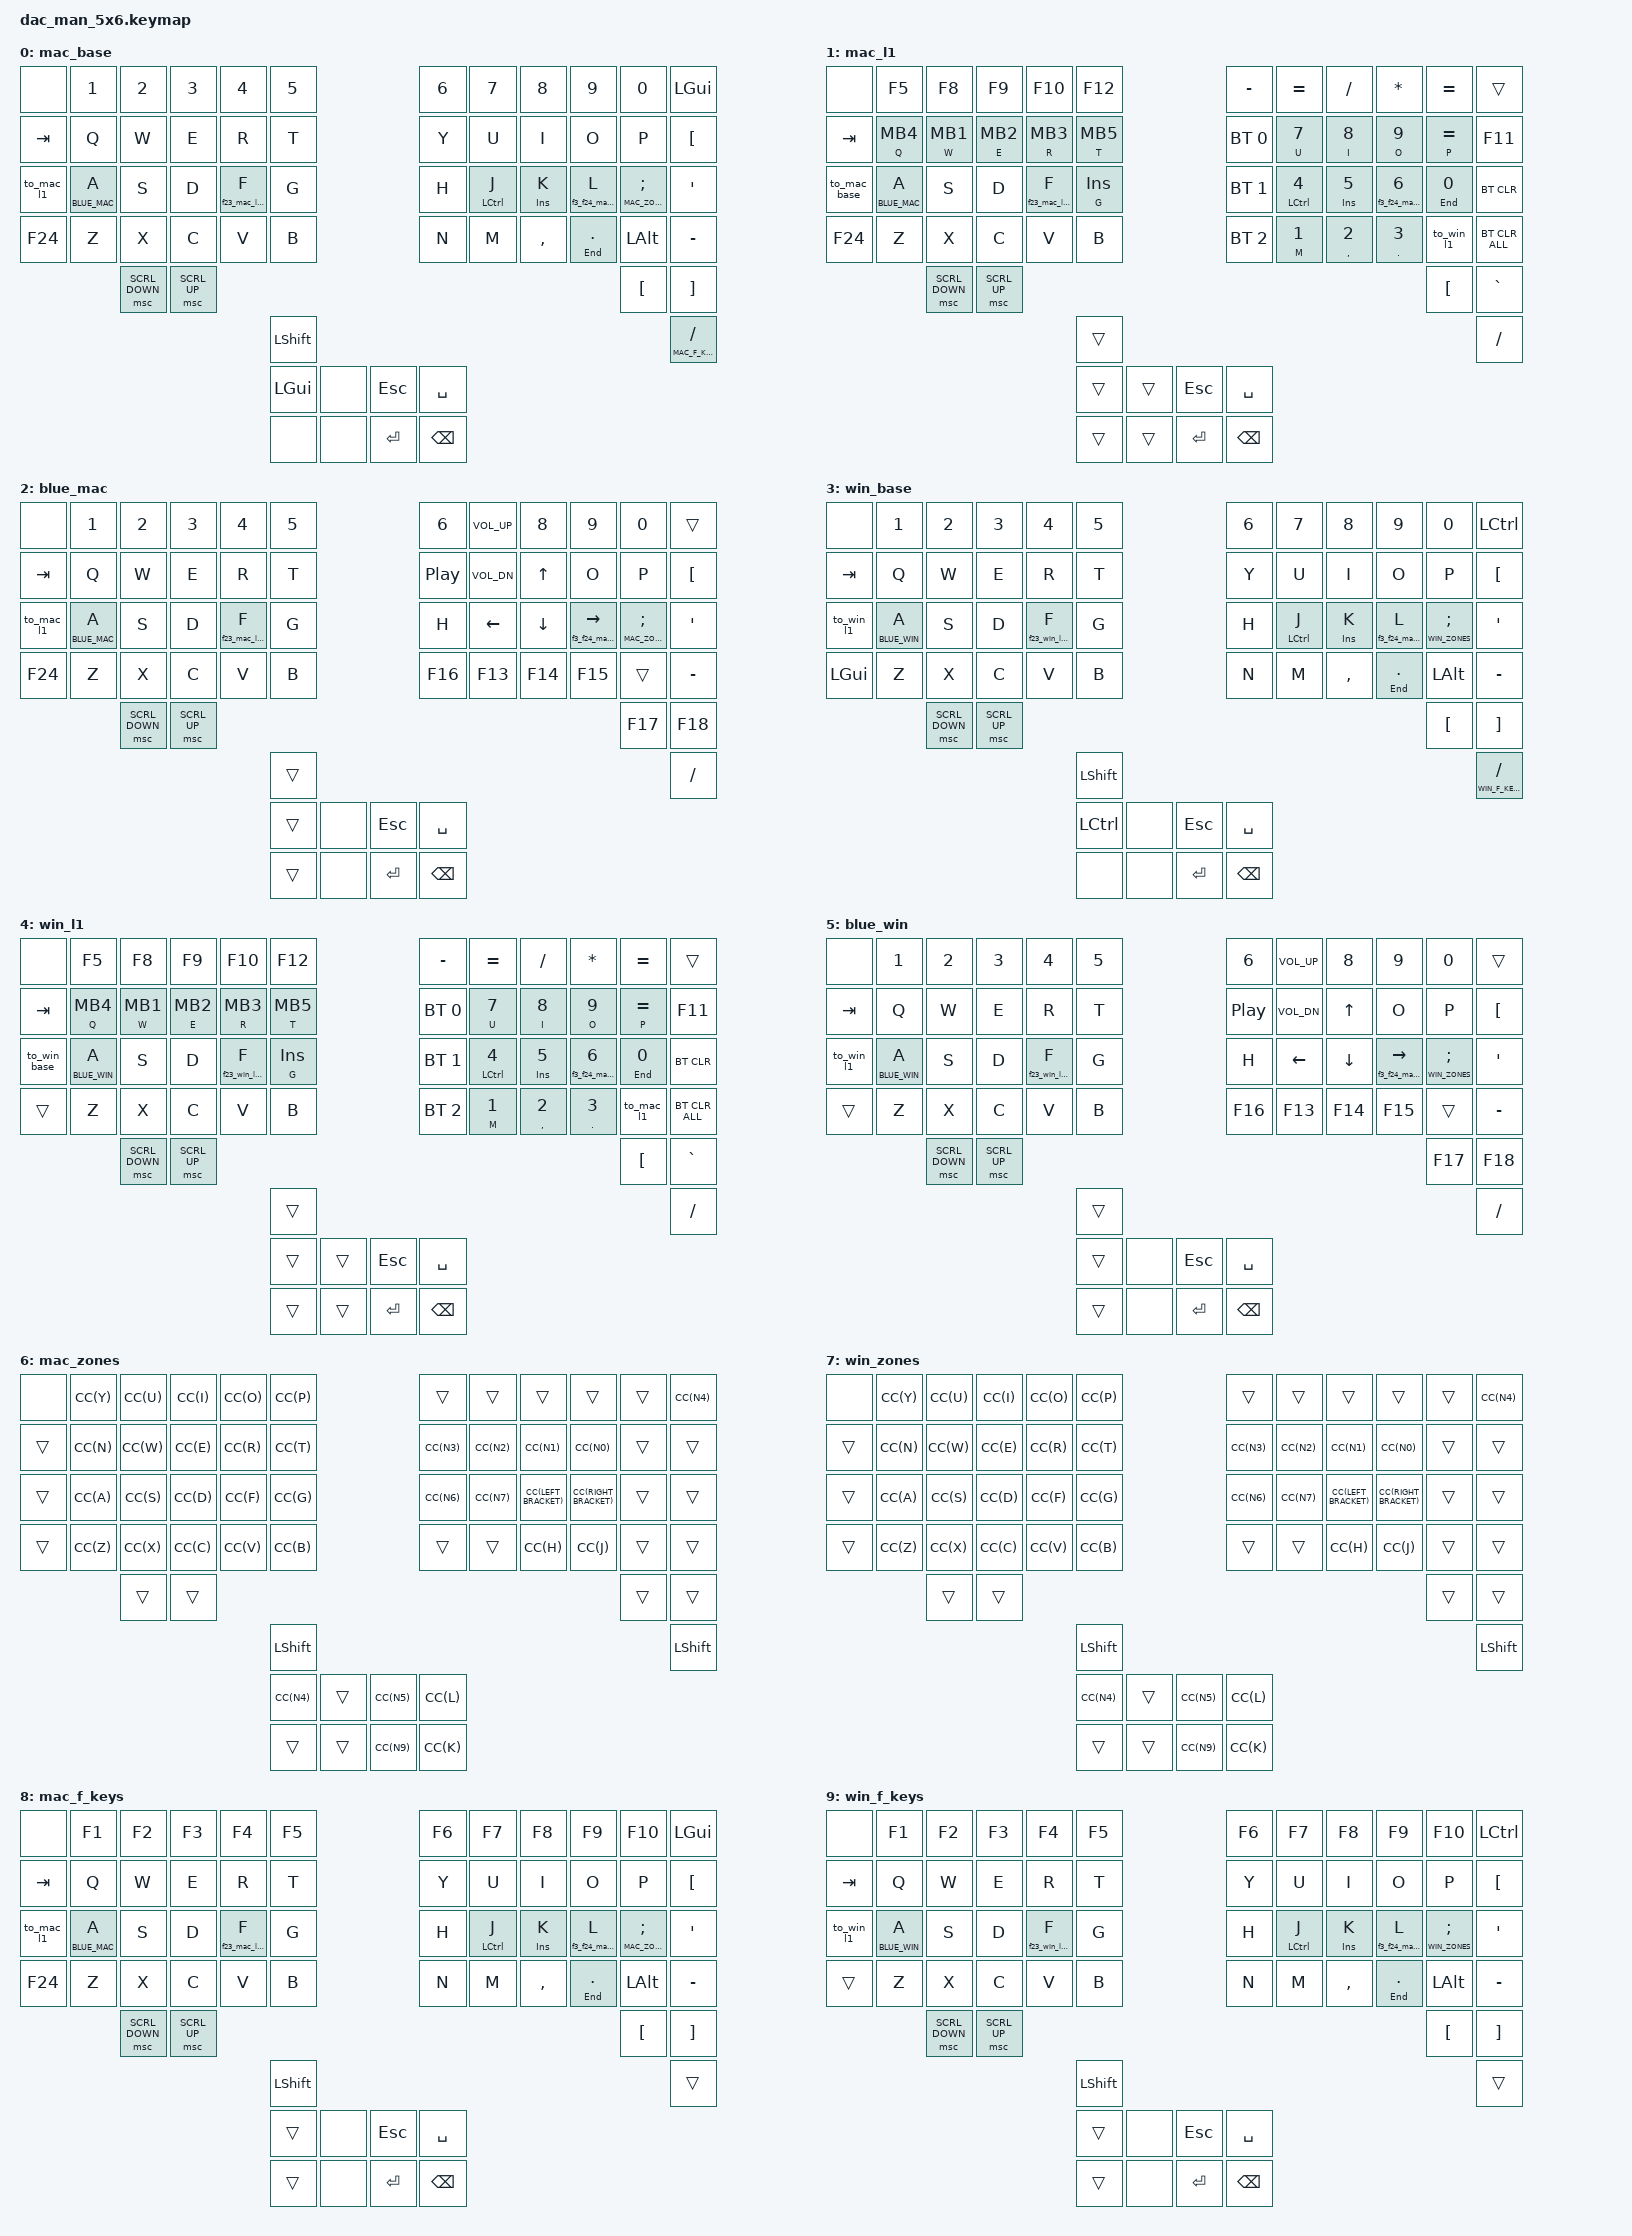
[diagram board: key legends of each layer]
#include <behaviors.dtsi>
#include <dt-bindings/zmk/bt.h>
#include <dt-bindings/zmk/keys.h>
#include <dt-bindings/zmk/pointing.h>

#define MAC_BASE   0
#define MAC_L1     1
#define BLUE_MAC   2
#define WIN_BASE   3
#define WIN_L1     4
#define BLUE_WIN   5
#define MAC_ZONES  6
#define WIN_ZONES  7
#define MAC_F_KEYS 8
#define WIN_F_KEYS 9

// Hyper key (Shift + Ctrl + Alt + Gui)
#define HYP(key) LS(LC(LA(LG(key))))
// Command + Control
#define CC(key) LC(LG(key))

/ {
    macros {
        to_mac_base: to_mac_base {
            compatible = "zmk,behavior-macro";
            #binding-cells = <0>;
            bindings = <&to MAC_BASE>, <&kp F19>;
        };

        to_mac_l1: to_mac_l1 {
            compatible = "zmk,behavior-macro";
            #binding-cells = <0>;
            bindings = <&to MAC_L1>, <&kp F20>;
        };

        to_win_base: to_win_base {
            compatible = "zmk,behavior-macro";
            #binding-cells = <0>;
            bindings = <&to WIN_BASE>, <&kp F21>;
        };

        to_win_l1: to_win_l1 {
            compatible = "zmk,behavior-macro";
            #binding-cells = <0>;
            bindings = <&to WIN_L1>, <&kp F22>;
        };

        f23_mac_layer: f23_mac_layer {
            compatible = "zmk,behavior-macro-one-param";
            #binding-cells = <1>;
            wait-ms = <0>;
            tap-ms = <0>;
            bindings =
                <&macro_press>, <&mo BLUE_MAC>,
                <&macro_tap>, <&kp F23>,
                <&macro_pause_for_release>,
                <&macro_release>, <&mo BLUE_MAC>;
        };

        f23_win_layer: f23_win_layer {
            compatible = "zmk,behavior-macro-one-param";
            #binding-cells = <1>;
            wait-ms = <0>;
            tap-ms = <0>;
            bindings =
                <&macro_press>, <&mo BLUE_WIN>,
                <&macro_tap>, <&kp F23>,
                <&macro_pause_for_release>,
                <&macro_release>, <&mo BLUE_WIN>;
        };

        f3_f24_macro: f3_f24_macro {
            compatible = "zmk,behavior-macro-one-param";
            #binding-cells = <1>;
            wait-ms = <0>;
            tap-ms = <0>;
            bindings =
                <&macro_press>, <&kp F24>,
                <&macro_press>, <&kp F3>,
                <&macro_pause_for_release>,
                <&macro_release>, <&kp F3>,
                <&macro_release>, <&kp F24>;
        };
    };

    behaviors {
        ht_tog: hold_tap_toggle {
            compatible = "zmk,behavior-hold-tap";
            #binding-cells = <2>;
            flavor = "tap-preferred";
            tapping-term-ms = <300>;
            require-prior-idle-ms = <350>;
            bindings = <&tog>, <&kp>;
        };

        ht_kp: hold_tap_key {
            compatible = "zmk,behavior-hold-tap";
            #binding-cells = <2>;
            flavor = "tap-preferred";
            tapping-term-ms = <300>;
            require-prior-idle-ms = <350>;
            bindings = <&kp>, <&kp>;
        };

        lt_kp: layer_tap_key {
            compatible = "zmk,behavior-hold-tap";
            #binding-cells = <2>;
            flavor = "tap-preferred";
            tapping-term-ms = <300>;
            require-prior-idle-ms = <350>;
            bindings = <&mo>, <&kp>;
        };

        lt_long: layer_tap_long {
            compatible = "zmk,behavior-hold-tap";
            #binding-cells = <2>;
            flavor = "tap-preferred";
            tapping-term-ms = <500>;
            require-prior-idle-ms = <350>;
            bindings = <&mo>, <&kp>;
        };

        ht_f_mac: ht_f_mac {
            compatible = "zmk,behavior-hold-tap";
            #binding-cells = <2>;
            flavor = "tap-preferred";
            tapping-term-ms = <300>;
            require-prior-idle-ms = <350>;
            bindings = <&f23_mac_layer>, <&kp>;
        };

        ht_f_win: ht_f_win {
            compatible = "zmk,behavior-hold-tap";
            #binding-cells = <2>;
            flavor = "tap-preferred";
            tapping-term-ms = <300>;
            require-prior-idle-ms = <350>;
            bindings = <&f23_win_layer>, <&kp>;
        };

        ht_l1_kp: hold_tap_l1_kp {
            compatible = "zmk,behavior-hold-tap";
            #binding-cells = <2>;
            flavor = "tap-preferred";
            tapping-term-ms = <500>;
            require-prior-idle-ms = <150>;
            bindings = <&kp>, <&kp>;
        };

        ht_l1_mkp: hold_tap_l1_mkp {
            compatible = "zmk,behavior-hold-tap";
            #binding-cells = <2>;
            flavor = "tap-preferred";
            tapping-term-ms = <500>;
            require-prior-idle-ms = <150>;
            bindings = <&kp>, <&mkp>;
        };

        ht_f3_f24: ht_f3_f24 {
            compatible = "zmk,behavior-hold-tap";
            #binding-cells = <2>;
            flavor = "tap-preferred";
            tapping-term-ms = <300>;
            require-prior-idle-ms = <350>;
            bindings = <&f3_f24_macro>, <&kp>;
        };

        ht_l1_f3_f24: ht_l1_f3_f24 {
            compatible = "zmk,behavior-hold-tap";
            #binding-cells = <2>;
            flavor = "tap-preferred";
            tapping-term-ms = <500>;
            require-prior-idle-ms = <150>;
            bindings = <&f3_f24_macro>, <&kp>;
        };
    };

    keymap {
        compatible = "zmk,keymap";

        // ================= MAC OS LAYERS =================

        mac_base {
            bindings = <
&none       &kp N1              &kp N2          &kp N3          &kp N4        &kp N5                                                                                                                                                                                                                                                                                                                        &kp N6          &kp N7         &kp N8          &kp N9             &kp N0                     &kp LGUI
&kp TAB     &kp Q               &kp W           &kp E           &kp R         &kp T                                                                                                                                                                                                                                                                                                                         &kp Y           &kp U          &kp I           &kp O              &kp P                      &kp LEFT_BRACKET
&to_mac_l1  &ht_tog BLUE_MAC A  &kp S           &kp D           &ht_f_mac 0 F &kp G                                                                                                                                                                                                                                                                                                                         &kp H           &ht_kp LCTRL J &ht_kp INSERT K &ht_f3_f24 0 L     &lt_kp MAC_ZONES SEMICOLON &kp SQT
&kp F24     &kp Z               &kp X           &kp C           &kp V         &kp B                                                                                                                                                                                                                                                                                                                         &kp N           &kp M          &kp COMMA       &ht_kp END DOT     &kp LALT                   &kp MINUS
                                &msc SCRL_DOWN  &msc SCRL_UP                                                                                                                                                                                                                                                                                                                                                                                                                      &kp LEFT_BRACKET           &kp RIGHT_BRACKET
                                                                              &kp LSHIFT                                                                                                                                                                                                                                                                                                                                                                                                                 &lt_long MAC_F_KEYS SLASH
                                                                                              &kp LGUI  &none  &kp ESCAPE  &kp SPACE
                                                                                              &none     &none  &kp RET     &kp BACKSPACE
            >;
        };

        mac_l1 {
            bindings = <
&none        &kp F5             &kp F8           &kp F9           &kp F10          &kp F12                                                                                                                                                                                                                                                                                                                      &kp MINUS       &kp EQUAL            &kp SLASH            &kp ASTERISK          &kp EQUAL              &trans
&kp TAB      &ht_l1_mkp Q MB4   &ht_l1_mkp W MB1 &ht_l1_mkp E MB2 &ht_l1_mkp R MB3 &ht_l1_mkp T MB5                                                                                                                                                                                                                                                                                                             &bt BT_SEL 0    &ht_l1_kp U NUMBER_7 &ht_l1_kp I NUMBER_8 &ht_l1_kp O NUMBER_9  &ht_l1_kp P EQUAL      &kp F11
&to_mac_base &ht_tog BLUE_MAC A &kp S            &kp D            &ht_f_mac 0 F    &ht_l1_kp G INSERT                                                                                                                                                                                                                                                                                                           &bt BT_SEL 1    &ht_l1_kp LCTRL NUMBER_4 &ht_l1_kp INSERT NUMBER_5 &ht_l1_f3_f24 0 NUMBER_6 &ht_l1_kp END NUMBER_0 &bt BT_CLR
&kp F24      &kp Z              &kp X            &kp C            &kp V            &kp B                                                                                                                                                                                                                                                                                                                        &bt BT_SEL 2    &ht_l1_kp M NUMBER_1 &ht_l1_kp COMMA NUMBER_2 &ht_l1_kp DOT NUMBER_3 &to_win_l1             &bt BT_CLR_ALL
                                &msc SCRL_DOWN   &msc SCRL_UP                                                                                                                                                                                                                                                                                                                                                                                                                                       &kp LEFT_BRACKET       &kp GRAVE
                                                                                   &trans                                                                                                                                                                                                                                                                                                                                                                                                                                &kp SLASH
                                                                                                      &trans    &trans &kp ESC    &kp SPACE
                                                                                                      &trans    &trans &kp ENTER  &kp BACKSPACE
            >;
        };

        blue_mac {
            bindings = <
&none       &kp N1              &kp N2          &kp N3          &kp N4        &kp N5                                                                                                                                                                                                                                                                                                                        &kp N6          &kp C_VOL_UP  &kp N8          &kp N9             &kp N0                     &trans
&kp TAB     &kp Q               &kp W           &kp E           &kp R         &kp T                                                                                                                                                                                                                                                                                                                         &kp C_PP        &kp C_VOL_DN  &kp UP_ARROW    &kp O              &kp P                      &kp LEFT_BRACKET
&to_mac_l1  &ht_tog BLUE_MAC A  &kp S           &kp D           &ht_f_mac 0 F &kp G                                                                                                                                                                                                                                                                                                                         &kp H           &kp LEFT      &kp DOWN        &ht_f3_f24 0 RIGHT &lt_kp MAC_ZONES SEMICOLON &kp SQT
&kp F24     &kp Z               &kp X           &kp C           &kp V         &kp B                                                                                                                                                                                                                                                                                                                         &kp F16         &kp F13       &kp F14         &kp F15            &trans                     &kp MINUS
                                &msc SCRL_DOWN  &msc SCRL_UP                                                                                                                                                                                                                                                                                                                                                                                                                      &kp F17                    &kp F18
                                                                              &trans                                                                                                                                                                                                                                                                                                                                                                                                                     &kp SLASH
                                                                                              &trans    &none  &kp ESCAPE  &kp SPACE
                                                                                              &trans    &none  &kp RET     &kp BACKSPACE
            >;
        };

        // ================= WINDOWS LAYERS =================

        win_base {
            bindings = <
&none         &kp N1              &kp N2          &kp N3          &kp N4        &kp N5                                                                                                                                                                                                                                                                                                                        &kp N6          &kp N7         &kp N8          &kp N9             &kp N0                     &kp LCTRL
&kp TAB       &kp Q               &kp W           &kp E           &kp R         &kp T                                                                                                                                                                                                                                                                                                                         &kp Y           &kp U          &kp I           &kp O              &kp P                      &kp LEFT_BRACKET
&to_win_l1    &ht_tog BLUE_WIN A  &kp S           &kp D           &ht_f_win 0 F &kp G                                                                                                                                                                                                                                                                                                                         &kp H           &ht_kp LCTRL J &ht_kp INSERT K &ht_f3_f24 0 L     &lt_kp WIN_ZONES SEMICOLON &kp SQT
&kp LGUI      &kp Z               &kp X           &kp C           &kp V         &kp B                                                                                                                                                                                                                                                                                                                         &kp N           &kp M          &kp COMMA       &ht_kp END DOT     &kp LALT                   &kp MINUS
                                  &msc SCRL_DOWN  &msc SCRL_UP                                                                                                                                                                                                                                                                                                                                                                                                                        &kp LEFT_BRACKET           &kp RIGHT_BRACKET
                                                                                &kp LSHIFT                                                                                                                                                                                                                                                                                                                                                                                                                   &lt_long WIN_F_KEYS SLASH
                                                                                                &kp LCTRL         &none  &kp ESCAPE  &kp SPACE
                                                                                                &none             &none  &kp RET     &kp BACKSPACE
            >;
        };

        win_l1 {
            bindings = <
&none         &kp F5              &kp F8           &kp F9           &kp F10          &kp F12                                                                                                                                                                                                                                                                                                                      &kp MINUS       &kp EQUAL            &kp SLASH            &kp ASTERISK          &kp EQUAL              &trans
&kp TAB       &ht_l1_mkp Q MB4    &ht_l1_mkp W MB1 &ht_l1_mkp E MB2 &ht_l1_mkp R MB3 &ht_l1_mkp T MB5                                                                                                                                                                                                                                                                                                             &bt BT_SEL 0    &ht_l1_kp U NUMBER_7 &ht_l1_kp I NUMBER_8 &ht_l1_kp O NUMBER_9  &ht_l1_kp P EQUAL      &kp F11
&to_win_base  &ht_tog BLUE_WIN A  &kp S            &kp D            &ht_f_win 0 F    &ht_l1_kp G INSERT                                                                                                                                                                                                                                                                                                           &bt BT_SEL 1    &ht_l1_kp LCTRL NUMBER_4 &ht_l1_kp INSERT NUMBER_5 &ht_l1_f3_f24 0 NUMBER_6 &ht_l1_kp END NUMBER_0 &bt BT_CLR
&trans        &kp Z               &kp X            &kp C            &kp V            &kp B                                                                                                                                                                                                                                                                                                                        &bt BT_SEL 2    &ht_l1_kp M NUMBER_1 &ht_l1_kp COMMA NUMBER_2 &ht_l1_kp DOT NUMBER_3 &to_mac_l1             &bt BT_CLR_ALL
                                  &msc SCRL_DOWN   &msc SCRL_UP                                                                                                                                                                                                                                                                                                                                                                                                                                       &kp LEFT_BRACKET       &kp GRAVE
                                                                                     &trans                                                                                                                                                                                                                                                                                                                                                                                                                                  &kp SLASH
                                                                                                        &trans            &trans &kp ESC    &kp SPACE
                                                                                                        &trans            &trans &kp ENTER  &kp BACKSPACE
            >;
        };

        blue_win {
            bindings = <
&none         &kp N1              &kp N2          &kp N3          &kp N4        &kp N5                                                                                                                                                                                                                                                                                                                        &kp N6          &kp C_VOL_UP  &kp N8          &kp N9             &kp N0                     &trans
&kp TAB       &kp Q               &kp W           &kp E           &kp R         &kp T                                                                                                                                                                                                                                                                                                                         &kp C_PP        &kp C_VOL_DN  &kp UP_ARROW    &kp O              &kp P                      &kp LEFT_BRACKET
&to_win_l1    &ht_tog BLUE_WIN A  &kp S           &kp D           &ht_f_win 0 F &kp G                                                                                                                                                                                                                                                                                                                         &kp H           &kp LEFT      &kp DOWN        &ht_f3_f24 0 RIGHT &lt_kp WIN_ZONES SEMICOLON &kp SQT
&trans        &kp Z               &kp X           &kp C           &kp V         &kp B                                                                                                                                                                                                                                                                                                                         &kp F16         &kp F13       &kp F14         &kp F15            &trans                     &kp MINUS
                                  &msc SCRL_DOWN  &msc SCRL_UP                                                                                                                                                                                                                                                                                                                                                                                                                        &kp F17                    &kp F18
                                                                                &trans                                                                                                                                                                                                                                                                                                                                                                                                                       &kp SLASH
                                                                                                &trans    &none  &kp ESCAPE  &kp SPACE
                                                                                                &trans    &none  &kp RET     &kp BACKSPACE
            >;
        };

        // ================= MONITOR ZONES =================

        mac_zones {
            bindings = <
&none   &kp CC(Y) &kp CC(U) &kp CC(I) &kp CC(O) &kp CC(P)    &trans      &trans      &trans                &trans                &trans &kp CC(N4)
&trans  &kp CC(N) &kp CC(W) &kp CC(E) &kp CC(R) &kp CC(T)    &kp CC(N3)  &kp CC(N2)  &kp CC(N1)            &kp CC(N0)            &trans &trans
&trans  &kp CC(A) &kp CC(S) &kp CC(D) &kp CC(F) &kp CC(G)    &kp CC(N6)  &kp CC(N7)  &kp CC(LEFT_BRACKET)  &kp CC(RIGHT_BRACKET) &trans &trans
&trans  &kp CC(Z) &kp CC(X) &kp CC(C) &kp CC(V) &kp CC(B)    &trans      &trans      &kp CC(H)             &kp CC(J)             &trans &trans
                  &trans    &trans                                                                         &trans                &trans
                            &kp LSHIFT                                                                     &kp LSHIFT
                                      &kp CC(N4) &trans &kp CC(N5) &kp CC(L)
                                      &trans     &trans &kp CC(N9) &kp CC(K)
            >;
        };

        win_zones {
            bindings = <
&none   &kp CC(Y) &kp CC(U) &kp CC(I) &kp CC(O) &kp CC(P)    &trans      &trans      &trans                &trans                &trans &kp CC(N4)
&trans  &kp CC(N) &kp CC(W) &kp CC(E) &kp CC(R) &kp CC(T)    &kp CC(N3)  &kp CC(N2)  &kp CC(N1)            &kp CC(N0)            &trans &trans
&trans  &kp CC(A) &kp CC(S) &kp CC(D) &kp CC(F) &kp CC(G)    &kp CC(N6)  &kp CC(N7)  &kp CC(LEFT_BRACKET)  &kp CC(RIGHT_BRACKET) &trans &trans
&trans  &kp CC(Z) &kp CC(X) &kp CC(C) &kp CC(V) &kp CC(B)    &trans      &trans      &kp CC(H)             &kp CC(J)             &trans &trans
                  &trans    &trans                                                                         &trans                &trans
                            &kp LSHIFT                                                                     &kp LSHIFT
                                      &kp CC(N4) &trans &kp CC(N5) &kp CC(L)
                                      &trans     &trans &kp CC(N9) &kp CC(K)
            >;
        };

        // ================= F KEYS (MAC & WIN) =================

        mac_f_keys {
            bindings = <
&none       &kp F1              &kp F2          &kp F3          &kp F4        &kp F5                                                                                                                                                                                                                                                                                                                        &kp F6          &kp F7         &kp F8          &kp F9             &kp F10                    &kp LGUI
&kp TAB     &kp Q               &kp W           &kp E           &kp R         &kp T                                                                                                                                                                                                                                                                                                                         &kp Y           &kp U          &kp I           &kp O              &kp P                      &kp LEFT_BRACKET
&to_mac_l1  &ht_tog BLUE_MAC A  &kp S           &kp D           &ht_f_mac 0 F &kp G                                                                                                                                                                                                                                                                                                                         &kp H           &ht_kp LCTRL J &ht_kp INSERT K &ht_f3_f24 0 L     &lt_kp MAC_ZONES SEMICOLON &kp SQT
&kp F24     &kp Z               &kp X           &kp C           &kp V         &kp B                                                                                                                                                                                                                                                                                                                         &kp N           &kp M          &kp COMMA       &ht_kp END DOT     &kp LALT                   &kp MINUS
                                &msc SCRL_DOWN  &msc SCRL_UP                                                                                                                                                                                                                                                                                                                                                                                                                      &kp LEFT_BRACKET           &kp RIGHT_BRACKET
                                                                              &kp LSHIFT                                                                                                                                                                                                                                                                                                                                                                                                                 &trans
                                                                                              &trans    &none  &kp ESCAPE  &kp SPACE
                                                                                              &trans    &none  &kp RET     &kp BACKSPACE
            >;
        };

        win_f_keys {
            bindings = <
&none         &kp F1              &kp F2          &kp F3          &kp F4        &kp F5                                                                                                                                                                                                                                                                                                                        &kp F6          &kp F7         &kp F8          &kp F9             &kp F10                    &kp LCTRL
&kp TAB       &kp Q               &kp W           &kp E           &kp R         &kp T                                                                                                                                                                                                                                                                                                                         &kp Y           &kp U          &kp I           &kp O              &kp P                      &kp LEFT_BRACKET
&to_win_l1    &ht_tog BLUE_WIN A  &kp S           &kp D           &ht_f_win 0 F &kp G                                                                                                                                                                                                                                                                                                                         &kp H           &ht_kp LCTRL J &ht_kp INSERT K &ht_f3_f24 0 L     &lt_kp WIN_ZONES SEMICOLON &kp SQT
&trans        &kp Z               &kp X           &kp C           &kp V         &kp B                                                                                                                                                                                                                                                                                                                         &kp N           &kp M          &kp COMMA       &ht_kp END DOT     &kp LALT                   &kp MINUS
                                  &msc SCRL_DOWN  &msc SCRL_UP                                                                                                                                                                                                                                                                                                                                                                                                                        &kp LEFT_BRACKET           &kp RIGHT_BRACKET
                                                                                &kp LSHIFT                                                                                                                                                                                                                                                                                                                                                                                                                   &trans
                                                                                                &trans    &none  &kp ESCAPE  &kp SPACE
                                                                                                &trans    &none  &kp RET     &kp BACKSPACE
            >;
        };
    };
};
